# EFR32FG25B222F1920IM56 register map
Vendor: Silicon Labs; Series: EFR32; File version: B
Registers are 32-bit, read-write, reset 0x0 unless marked. A register's access mark holds for its fields unless they carry their own. Offsets are from the block's base; [hi:lo] are bit positions; 'fields as' and 'values as' point back to an identical list.

## PFMXPPRF_NS — PFMXPPRF_NS Registers
Base 0x500C4000
Same registers: PFMXPPRF_S 0x400C4000
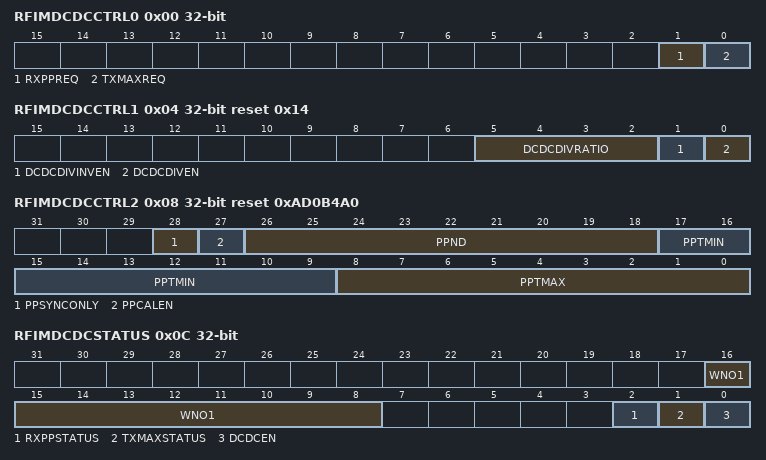
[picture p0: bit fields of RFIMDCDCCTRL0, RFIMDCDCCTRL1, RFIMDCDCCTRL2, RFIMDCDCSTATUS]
0x00 RFIMDCDCCTRL0
  [1] RXPPREQ, [0] TXMAXREQ
0x04 RFIMDCDCCTRL1 reset 0x14
  [5:2] DCDCDIVRATIO
    0=DIVRATIO8 (Dividing master_rf clk by 8, D=50%); 1=DIVRATIO9 (Dividing master_rf clk by 9, D=44.4%); 2=DIVRATIO10 (Dividing master_rf clk by 10, D=40%); 3=DIVRATIO11 (Dividing master_rf clk by 11, D=36.4%); 4=DIVRATIO12 (Dividing master_rf clk by 12, D=50%); 5=DIVRATIO13 (Dividing master_rf clk by 13, D=46.2%); 6=DIVRATIO14 (Dividing master_rf clk by 14, D=42.9%); 7=DIVRATIO15 (Dividing master_rf clk by 15, D=40%); 8=DIVRATIO16 (Dividing master_rf clk by 16, D=50%); 9=DIVRATIO17 (Dividing master_rf clk by 17, D=47.1%); 10=DIVRATIO18 (Dividing master_rf clk by 18, D=44.4%); 11=DIVRATIO19 (Dividing master_rf clk by 19, D=42.1%); 12=DIVRATIO20 (Dividing master_rf clk by 20, D=60%); 13=DIVRATIO21 (Dividing master_rf clk by 21, D=57.1%); 14=DIVRATIO22 (Dividing master_rf clk by 22, D=54.5%); 15=DIVRATIO23 (Dividing master_rf clk by 23, D=52.2%)
  [1] DCDCDIVINVEN — DCDC DIV Inverter Enable
  [0] DCDCDIVEN — DCDC DIV Enable
0x08 RFIMDCDCCTRL2 reset 0xAD0B4A0
  [28] PPSYNCONLY — Pulse Pairing Sync Only
  [27] PPCALEN — Pulse Pairing Calibration Loop Enable
  [26:18] PPND — Pulse Pairing Period
  [17:9] PPTMIN — Pulse Pairing Time Min
  [8:0] PPTMAX — Pulse Pairing Time Max
0x0C RFIMDCDCSTATUS ro
  [16:8] WNO1 — Cal Loop WNO1 value
  [2] RXPPSTATUS
  [1] TXMAXSTATUS
  [0] DCDCEN — DCDC Enable Status
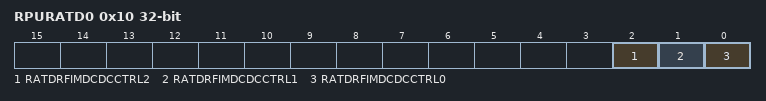
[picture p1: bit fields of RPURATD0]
0x10 RPURATD0 — Protected register address = (RPURATD register index X 32 + RPURATD bit index) X 4.
  [2] RATDRFIMDCDCCTRL2 — RFIMDCDCCTRL2 Protection Bit
  [1] RATDRFIMDCDCCTRL1 — RFIMDCDCCTRL1 Protection Bit
  [0] RATDRFIMDCDCCTRL0 — RFIMDCDCCTRL0 Protection Bit

## RFFPLL0_NS — RFFPLL0_NS Registers
Base 0x500C8000
Same registers: RFFPLL0_S 0x400C8000
0x00 IPVERSION ro reset 0x1
  [31:0] IPVERSION — IP Version ID
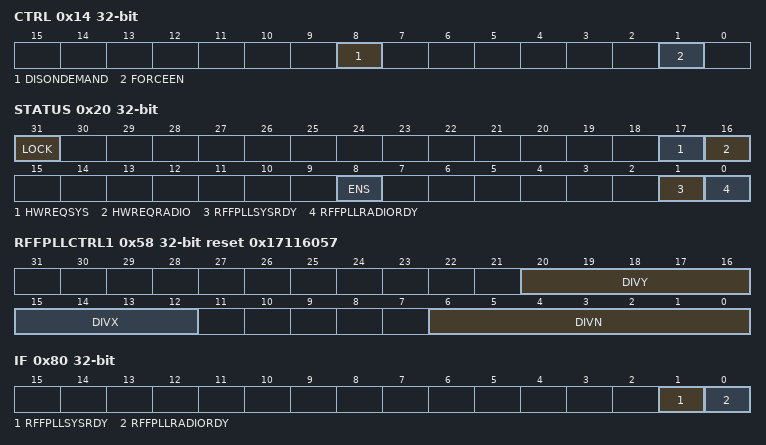
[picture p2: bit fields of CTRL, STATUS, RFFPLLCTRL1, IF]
0x14 CTRL
  [8] DISONDEMAND — Disable On-demand request
  [1] FORCEEN — Force PLL Enable
0x20 STATUS ro
  [31] LOCK — Configuration Lock Status
    0=UNLOCKED (Configuration lock is unlocked); 1=LOCKED (Configuration lock is locked)
  [17] HWREQSYS — PLL Digital System Output Requested
  [16] HWREQRADIO — PLL Radio Output Requested
  [8] ENS — Enabled Status
  [1] RFFPLLSYSRDY — Digital System Clock Output Ready
  [0] RFFPLLRADIORDY — Radio Clock Output Ready
0x58 RFFPLLCTRL1 reset 0x17116057
  [20:16] DIVY — Clock Divider Ratio for digital
  [15:12] DIVX — Clock Divider Ratio for Radio
  [6:0] DIVN — Feedback Divider Ratio
0x80 IF
  [1] RFFPLLSYSRDY — Digital System Output Ready Interrupt
  [0] RFFPLLRADIORDY — Radio Output Ready Interrupt
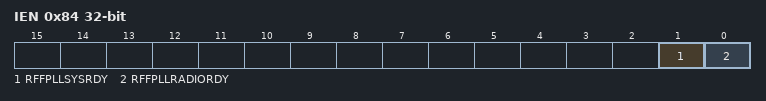
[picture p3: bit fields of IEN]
0x84 IEN
  fields as IF
0xB0 LOCK wo reset 0x85A9
  [15:0] LOCKKEY — Configuration Lock Key
    0x85A9=UNLOCK (Write this value to unlock)

## SCRATCHPAD_NS — SCRATCHPAD_NS Registers
Base 0x50000000
Same registers: SCRATCHPAD_S 0x40000000
0x00 SREG0 — Used for SIMCTRL Pointer in Verification Environment
  [31:0] SCRATCH — Scratch Pad Register
0x04 SREG1 — Used for SIMCTRL Data Access in Verification Environment
  [31:0] SCRATCH

## SEMAILBOX_NS_HOST — SEMAILBOX_NS_HOST Registers
Base 0x5C000000
Same registers: SEMAILBOX_S_HOST 0x4C000000
0x00 FIFO — A write access to any address in this area will be mapped to the TX FIFO (only for the payload). A read access to any address in this area will be mapped to the RX FIFO (only for the payload). Using an address range (16 x 32-bit) rather than one single address mapped to the FIFO allows using incremental bursts.
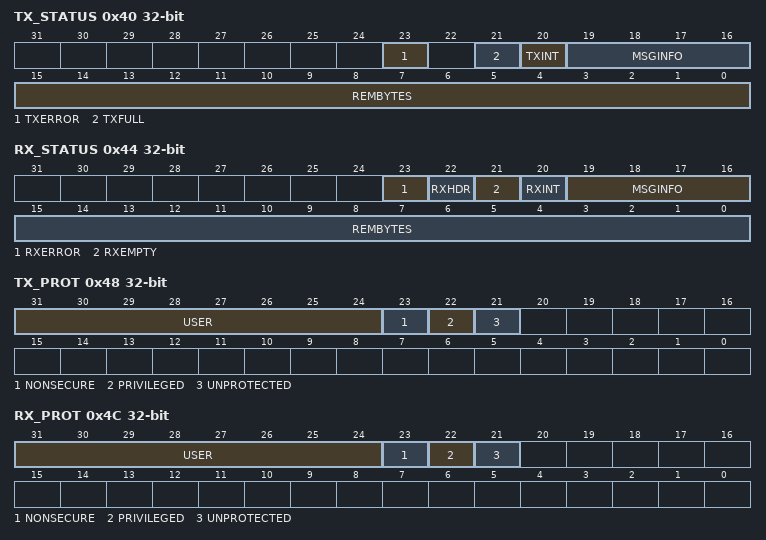
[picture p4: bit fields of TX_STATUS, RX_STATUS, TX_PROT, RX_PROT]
0x40 TX_STATUS ro
  [23] TXERROR, [21] TXFULL, [20] TXINT, [19:16] MSGINFO, [15:0] REMBYTES
0x44 RX_STATUS ro
  [23] RXERROR, [22] RXHDR, [21] RXEMPTY, [20] RXINT, [19:16] MSGINFO, [15:0] REMBYTES
0x48 TX_PROT ro — TX Protection register.
  [31:24] USER, [23] NONSECURE, [22] PRIVILEGED, [21] UNPROTECTED
0x4C RX_PROT ro — RX Protection register.
  [31:24] USER, [23] NONSECURE, [22] PRIVILEGED, [21] UNPROTECTED
0x50 TX_HEADER wo — A write access to this register will be mapped to the TX FIFO (only for header).
  [31:0] TXHEADER
0x54 RX_HEADER ro — A read access to this register will be mapped to the RX FIFO (only for the header).
  [31:0] RXHEADER
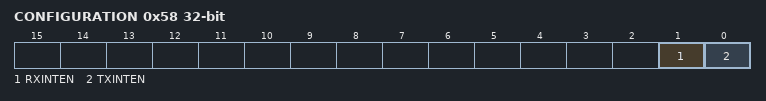
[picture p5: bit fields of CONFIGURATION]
0x58 CONFIGURATION
  [1] RXINTEN, [0] TXINTEN
